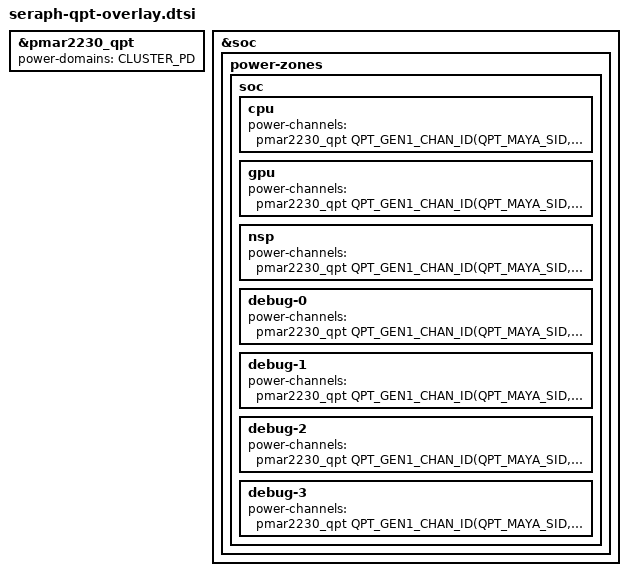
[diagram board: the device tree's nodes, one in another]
#include <dt-bindings/soc/qcom,qpt-gen1-channels.h>

&pmar2230_qpt {
	status = "okay";
	power-domains = <&CLUSTER_PD>;
};

&soc {
	power-zones {
		soc {
			cpu {
				power-channels =
					<&pmar2230_qpt QPT_GEN1_CHAN_ID(QPT_MAYA_SID, QPT_S1_REG)>;
			};

			gpu {
				power-channels =
					<&pmar2230_qpt QPT_GEN1_CHAN_ID(QPT_MAYA_SID, QPT_S9_REG)>;
			};

			nsp {
				power-channels =
					<&pmar2230_qpt QPT_GEN1_CHAN_ID(QPT_MAYA_SID, QPT_S2_REG)>;
			};

			debug-0 {
				power-channels =
					<&pmar2230_qpt QPT_GEN1_CHAN_ID(QPT_MAYA_SID, QPT_S10_REG)>;
			};

			debug-1 {
				power-channels =
					<&pmar2230_qpt QPT_GEN1_CHAN_ID(QPT_MAYA_SID, QPT_S4_REG)>;
			};

			debug-2 {
				power-channels =
					<&pmar2230_qpt QPT_GEN1_CHAN_ID(QPT_MAYA_SID, QPT_S5_REG)>;
			};

			debug-3 {
				power-channels =
					<&pmar2230_qpt QPT_GEN1_CHAN_ID(QPT_MAYA_SID, QPT_S6_REG)>;
			};
		};
	};
};
